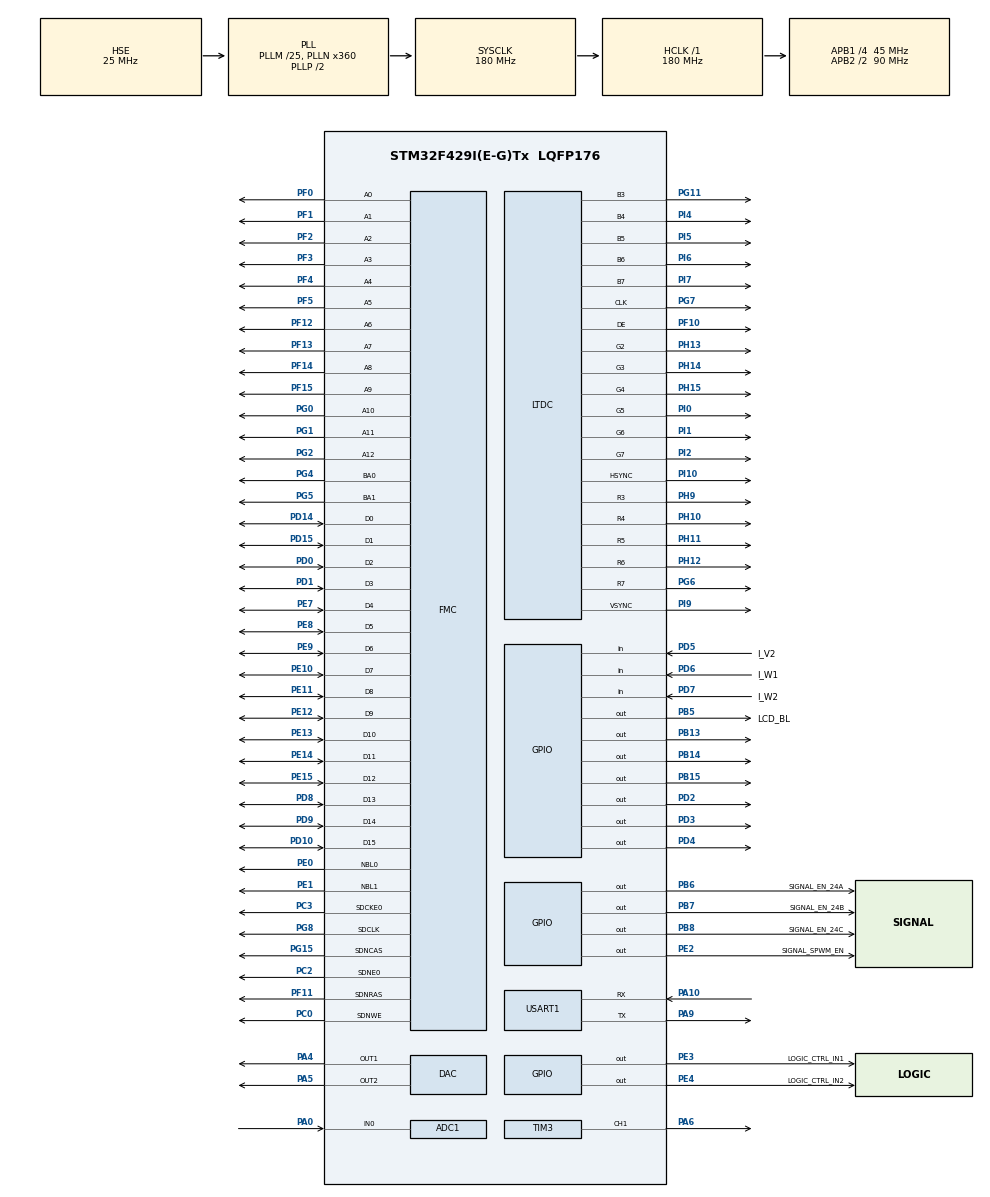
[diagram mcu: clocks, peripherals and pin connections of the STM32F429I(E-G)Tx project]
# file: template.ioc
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ADC1.Channel-0\#ChannelRegularConversion=ADC_CHANNEL_0
ADC1.ClockPrescaler=ADC_CLOCK_SYNC_PCLK_DIV6
ADC1.ContinuousConvMode=DISABLE
ADC1.DMAContinuousRequests=ENABLE
ADC1.EOCSelection=ADC_EOC_SEQ_CONV
ADC1.ExternalTrigConv=ADC_EXTERNALTRIGCONV_T2_TRGO
ADC1.NbrOfConversion=1
ADC1.NbrOfConversionFlag=1
ADC1.Rank-0\#ChannelRegularConversion=1
ADC1.SamplingTime-0\#ChannelRegularConversion=ADC_SAMPLETIME_56CYCLES
ADC1.ScanConvMode=ENABLE
ADC1.master=1
DAC.DAC_Trigger=DAC_TRIGGER_NONE
Dma.ADC1.0.Direction=DMA_PERIPH_TO_MEMORY
Dma.ADC1.0.FIFOMode=DMA_FIFOMODE_DISABLE
Dma.ADC1.0.Instance=DMA2_Stream0
Dma.ADC1.0.MemDataAlignment=DMA_MDATAALIGN_HALFWORD
Dma.ADC1.0.MemInc=DMA_MINC_ENABLE
Dma.ADC1.0.Mode=DMA_CIRCULAR
Dma.ADC1.0.PeriphDataAlignment=DMA_PDATAALIGN_HALFWORD
Dma.ADC1.0.PeriphInc=DMA_PINC_DISABLE
Dma.ADC1.0.Priority=DMA_PRIORITY_HIGH
Dma.Request0=ADC1
FATFS._CODE_PAGE=437
FATFS._FS_NORTC=1
FATFS._MAX_LFN=255
FATFS._MAX_SS=4096
FATFS._MIN_SS=4096
FATFS._NORTC_MDAY=7
FATFS._NORTC_YEAR=2022
FATFS._STRF_ENCODE=3
FATFS._USE_LFN=2
FMC.CASLatency1=FMC_SDRAM_CAS_LATENCY_3
FMC.ColumnBitsNumber1=FMC_SDRAM_COLUMN_BITS_NUM_9
FMC.ExitSelfRefreshDelay1=8
FMC.LoadToActiveDelay1=2
FMC.RCDDelay1=2
FMC.RPDelay1=2
FMC.RPDelay2=2
FMC.ReadBurst1=FMC_SDRAM_RBURST_ENABLE
FMC.ReadBurst2=FMC_SDRAM_RBURST_ENABLE
FMC.ReadPipeDelay1=FMC_SDRAM_RPIPE_DELAY_1
FMC.ReadPipeDelay2=FMC_SDRAM_RPIPE_DELAY_1
FMC.RowCycleDelay1=6
FMC.RowCycleDelay2=6
FMC.SDClockPeriod1=FMC_SDRAM_CLOCK_PERIOD_2
FMC.SDClockPeriod2=FMC_SDRAM_CLOCK_PERIOD_2
FMC.SelfRefreshTime1=6
FMC.WriteRecoveryTime1=4
FREERTOS.BinarySemaphores01=myBinarySemAnalog,Dynamic,NULL
FREERTOS.Tasks01=touchGFX,1,4096,TouchGFX_Task,As weak,NULL,Dynamic,NULL,NULL;myTask02,0,2048,StartTask02,Default,NULL,Dynamic,NULL,NULL
FREERTOS.Timers01=myTimer01,Callback01,osTimerPeriodic,Default,NULL,Dynamic,NULL
FREERTOS.configTOTAL_HEAP_SIZE=32768
LTDC.ActiveH=600
LTDC.ActiveW=1024
LTDC.Alpha_L0=255
LTDC.FBStartAdress_L0=0xC0000000
LTDC.HBP=140
LTDC.HFP=160
LTDC.HSync=20
LTDC.ImageHeight_L0=600
LTDC.ImageWidth_L0=1024
LTDC.Layers=0
LTDC.PixelFormat_L0=LTDC_PIXEL_FORMAT_RGB565
LTDC.VBP=20
LTDC.VFP=12
LTDC.VSync=3
LTDC.WindowX1_L0=1024
LTDC.WindowY1_L0=600
Mcu.Family=STM32F4
Mcu.Name=STM32F429I(E-G)Tx
Mcu.Package=LQFP176
NVIC.ADC_IRQn=true\:5\:0\:false\:false\:true\:true\:true\:true\:true
NVIC.DMA2D_IRQn=true\:5\:0\:false\:false\:true\:true\:true\:true\:true
NVIC.DMA2_Stream0_IRQn=true\:9\:0\:true\:false\:true\:false\:false\:true\:true
NVIC.LTDC_IRQn=true\:9\:0\:true\:false\:true\:true\:true\:true\:true
NVIC.PriorityGroup=NVIC_PRIORITYGROUP_4
NVIC.TIM6_DAC_IRQn=true\:5\:0\:false\:false\:true\:false\:true\:true\:true
NVIC.TIM7_IRQn=true\:15\:0\:false\:false\:true\:false\:false\:true\:true
NVIC.TimeBase=TIM7_IRQn
NVIC.TimeBaseIP=TIM7
PA0/WKUP.Signal=ADCx_IN0
PA10.Mode=Asynchronous
PA10.Signal=USART1_RX
PA13.Mode=Serial_Wire
PA13.Signal=SYS_JTMS-SWDIO
PA14.Mode=Serial_Wire
PA14.Signal=SYS_JTCK-SWCLK
PA4.Signal=COMP_DAC1_group
PA5.Signal=COMP_DAC2_group
PA6.Signal=S_TIM3_CH1
PA9.Mode=Asynchronous
PA9.Signal=USART1_TX
PB13.Signal=GPIO_Output
PB14.Signal=GPIO_Output
PB15.Signal=GPIO_Output
PB5.GPIO_Label=LCD_BL
PB5.GPIO_Speed=GPIO_SPEED_FREQ_HIGH
PB5.Signal=GPIO_Output
PB6.GPIO_Label=SIGNAL_EN_24A
PB6.GPIO_Speed=GPIO_SPEED_FREQ_HIGH
PB6.Signal=GPIO_Output
PB7.GPIO_Label=SIGNAL_EN_24B
PB7.GPIO_Speed=GPIO_SPEED_FREQ_HIGH
PB7.Signal=GPIO_Output
PB8.GPIO_Label=SIGNAL_EN_24C
PB8.GPIO_Speed=GPIO_SPEED_FREQ_HIGH
PB8.Signal=GPIO_Output
PC0.Signal=FMC_SDNWE
PC14/OSC32_IN.Mode=LSE-External-Oscillator
PC14/OSC32_IN.Signal=RCC_OSC32_IN
PC15/OSC32_OUT.Mode=LSE-External-Oscillator
PC15/OSC32_OUT.Signal=RCC_OSC32_OUT
PC2.Mode=SdramChipSelect1_1
PC2.Signal=FMC_SDNE0
PC3.Mode=SdramChipSelect1_1
PC3.Signal=FMC_SDCKE0
PD0.Signal=FMC_D2_DA2
PD1.Signal=FMC_D3_DA3
PD10.Signal=FMC_D15_DA15
PD14.Signal=FMC_D0_DA0
PD15.Signal=FMC_D1_DA1
PD2.Signal=GPIO_Output
PD3.Signal=GPIO_Output
PD4.Signal=GPIO_Output
PD5.GPIO_Label=I_V2
PD5.Signal=GPIO_Input
PD6.GPIO_Label=I_W1
PD6.Signal=GPIO_Input
PD7.GPIO_Label=I_W2
PD7.Signal=GPIO_Input
PD8.Signal=FMC_D13_DA13
PD9.Signal=FMC_D14_DA14
PE0.Signal=FMC_NBL0
PE1.Signal=FMC_NBL1
PE10.Signal=FMC_D7_DA7
PE11.Signal=FMC_D8_DA8
PE12.Signal=FMC_D9_DA9
PE13.Signal=FMC_D10_DA10
PE14.Signal=FMC_D11_DA11
PE15.Signal=FMC_D12_DA12
PE2.GPIO_Label=SIGNAL_SPWM_EN
PE2.GPIO_Speed=GPIO_SPEED_FREQ_HIGH
PE2.Signal=GPIO_Output
PE3.GPIO_Label=LOGIC_CTRL_IN1
PE3.GPIO_Speed=GPIO_SPEED_FREQ_HIGH
PE3.Signal=GPIO_Output
PE4.GPIO_Label=LOGIC_CTRL_IN2
PE4.GPIO_Speed=GPIO_SPEED_FREQ_HIGH
PE4.Signal=GPIO_Output
PE7.Signal=FMC_D4_DA4
PE8.Signal=FMC_D5_DA5
PE9.Signal=FMC_D6_DA6
PF0.Signal=FMC_A0
PF1.Signal=FMC_A1
PF10.GPIO_Speed=GPIO_SPEED_FREQ_VERY_HIGH
PF10.Mode=RGB565
PF10.Signal=LTDC_DE
PF11.Signal=FMC_SDNRAS
PF12.Signal=FMC_A6
PF13.Signal=FMC_A7
PF14.Signal=FMC_A8
PF15.Signal=FMC_A9
PF2.Signal=FMC_A2
PF3.Signal=FMC_A3
PF4.Signal=FMC_A4
PF5.Signal=FMC_A5
PG0.Signal=FMC_A10
PG1.Signal=FMC_A11
PG11.GPIO_Speed=GPIO_SPEED_FREQ_VERY_HIGH
PG11.Mode=RGB565
PG11.Signal=LTDC_B3
PG15.Signal=FMC_SDNCAS
PG2.Signal=FMC_A12
PG4.Signal=FMC_A14_BA0
PG5.Signal=FMC_A15_BA1
PG6.GPIO_Speed=GPIO_SPEED_FREQ_VERY_HIGH
PG6.Mode=RGB565
PG6.Signal=LTDC_R7
PG7.GPIO_Speed=GPIO_SPEED_FREQ_VERY_HIGH
PG7.Mode=RGB565
PG7.Signal=LTDC_CLK
PG8.Signal=FMC_SDCLK
PH0/OSC_IN.Mode=HSE-External-Oscillator
PH0/OSC_IN.Signal=RCC_OSC_IN
PH1/OSC_OUT.Mode=HSE-External-Oscillator
PH1/OSC_OUT.Signal=RCC_OSC_OUT
PH10.GPIO_Speed=GPIO_SPEED_FREQ_VERY_HIGH
PH10.Mode=RGB565
PH10.Signal=LTDC_R4
PH11.GPIO_Speed=GPIO_SPEED_FREQ_VERY_HIGH
PH11.Mode=RGB565
PH11.Signal=LTDC_R5
PH12.GPIO_Speed=GPIO_SPEED_FREQ_VERY_HIGH
PH12.Mode=RGB565
PH12.Signal=LTDC_R6
PH13.GPIO_Speed=GPIO_SPEED_FREQ_VERY_HIGH
PH13.Mode=RGB565
PH13.Signal=LTDC_G2
PH14.GPIO_Speed=GPIO_SPEED_FREQ_VERY_HIGH
PH14.Mode=RGB565
PH14.Signal=LTDC_G3
PH15.GPIO_Speed=GPIO_SPEED_FREQ_VERY_HIGH
PH15.Mode=RGB565
PH15.Signal=LTDC_G4
PH9.GPIO_Speed=GPIO_SPEED_FREQ_VERY_HIGH
PH9.Mode=RGB565
PH9.Signal=LTDC_R3
PI0.GPIO_Speed=GPIO_SPEED_FREQ_VERY_HIGH
PI0.Mode=RGB565
PI0.Signal=LTDC_G5
PI1.GPIO_Speed=GPIO_SPEED_FREQ_VERY_HIGH
PI1.Mode=RGB565
PI1.Signal=LTDC_G6
PI10.GPIO_Speed=GPIO_SPEED_FREQ_VERY_HIGH
PI10.Mode=RGB565
PI10.Signal=LTDC_HSYNC
PI2.GPIO_Speed=GPIO_SPEED_FREQ_VERY_HIGH
PI2.Mode=RGB565
PI2.Signal=LTDC_G7
PI4.GPIO_Speed=GPIO_SPEED_FREQ_VERY_HIGH
PI4.Mode=RGB565
PI4.Signal=LTDC_B4
PI5.GPIO_Speed=GPIO_SPEED_FREQ_VERY_HIGH
PI5.Mode=RGB565
PI5.Signal=LTDC_B5
PI6.GPIO_Speed=GPIO_SPEED_FREQ_VERY_HIGH
PI6.Mode=RGB565
PI6.Signal=LTDC_B6
PI7.GPIO_Speed=GPIO_SPEED_FREQ_VERY_HIGH
PI7.Mode=RGB565
PI7.Signal=LTDC_B7
PI9.GPIO_Speed=GPIO_SPEED_FREQ_VERY_HIGH
PI9.Mode=RGB565
PI9.Signal=LTDC_VSYNC
ProjectManager.HeapSize=0x1000
ProjectManager.StackSize=0x2000
ProjectManager.TargetToolchain=MDK-ARM V5
RCC.48MHZClocksFreq_Value=45000000
RCC.AHBFreq_Value=180000000
RCC.APB1CLKDivider=RCC_HCLK_DIV4
RCC.APB1Freq_Value=45000000
RCC.APB1TimFreq_Value=90000000
RCC.APB2CLKDivider=RCC_HCLK_DIV2
RCC.APB2Freq_Value=90000000
RCC.APB2TimFreq_Value=180000000
RCC.CortexFreq_Value=180000000
RCC.HCLKFreq_Value=180000000
RCC.HSE_VALUE=25000000
RCC.HSI_VALUE=16000000
RCC.PLLM=25
RCC.PLLN=360
RCC.PLLQ=8
RCC.PLLSAIN=168
RCC.PLLSourceVirtual=RCC_PLLSOURCE_HSE
RCC.SYSCLKFreq_VALUE=180000000
RCC.SYSCLKSource=RCC_SYSCLKSOURCE_PLLCLK
RCC.VCOOutputFreq_Value=360000000
SH.ADCx_IN0.0=ADC1_IN0,IN0
SH.COMP_DAC1_group.0=DAC_OUT1,DAC_OUT1
SH.COMP_DAC2_group.0=DAC_OUT2,DAC_OUT2
SH.FMC_A0.0=FMC_A0,13b-sda1
SH.FMC_A1.0=FMC_A1,13b-sda1
SH.FMC_A10.0=FMC_A10,13b-sda1
SH.FMC_A11.0=FMC_A11,13b-sda1
SH.FMC_A12.0=FMC_A12,13b-sda1
SH.FMC_A14_BA0.0=FMC_BA0,FourSdramBanks1
SH.FMC_A15_BA1.0=FMC_BA1,FourSdramBanks1
SH.FMC_A2.0=FMC_A2,13b-sda1
SH.FMC_A3.0=FMC_A3,13b-sda1
SH.FMC_A4.0=FMC_A4,13b-sda1
SH.FMC_A5.0=FMC_A5,13b-sda1
SH.FMC_A6.0=FMC_A6,13b-sda1
SH.FMC_A7.0=FMC_A7,13b-sda1
SH.FMC_A8.0=FMC_A8,13b-sda1
SH.FMC_A9.0=FMC_A9,13b-sda1
SH.FMC_D0_DA0.0=FMC_D0,sd-16b-d1
SH.FMC_D10_DA10.0=FMC_D10,sd-16b-d1
SH.FMC_D11_DA11.0=FMC_D11,sd-16b-d1
SH.FMC_D12_DA12.0=FMC_D12,sd-16b-d1
SH.FMC_D13_DA13.0=FMC_D13,sd-16b-d1
SH.FMC_D14_DA14.0=FMC_D14,sd-16b-d1
SH.FMC_D15_DA15.0=FMC_D15,sd-16b-d1
SH.FMC_D1_DA1.0=FMC_D1,sd-16b-d1
SH.FMC_D2_DA2.0=FMC_D2,sd-16b-d1
SH.FMC_D3_DA3.0=FMC_D3,sd-16b-d1
SH.FMC_D4_DA4.0=FMC_D4,sd-16b-d1
SH.FMC_D5_DA5.0=FMC_D5,sd-16b-d1
SH.FMC_D6_DA6.0=FMC_D6,sd-16b-d1
SH.FMC_D7_DA7.0=FMC_D7,sd-16b-d1
SH.FMC_D8_DA8.0=FMC_D8,sd-16b-d1
SH.FMC_D9_DA9.0=FMC_D9,sd-16b-d1
SH.FMC_NBL0.0=FMC_NBL0,Sd2ByteEnable1
SH.FMC_NBL1.0=FMC_NBL1,Sd2ByteEnable1
SH.FMC_SDCLK.0=FMC_SDCLK,13b-sda1
SH.FMC_SDNCAS.0=FMC_SDNCAS,13b-sda1
SH.FMC_SDNRAS.0=FMC_SDNRAS,13b-sda1
SH.FMC_SDNWE.0=FMC_SDNWE,13b-sda1
SH.S_TIM3_CH1.0=TIM3_CH1,PWM Generation1 CH1
STMicroelectronics.X-CUBE-TOUCHGFX.4.18.1.ApplicationCcGraphicsJjApplication=TouchGFXOoGenerator
STMicroelectronics.X-CUBE-TOUCHGFX.4.18.1.tgfx_address1=0xC0000000
STMicroelectronics.X-CUBE-TOUCHGFX.4.18.1.tgfx_address2=0xC012C000
STMicroelectronics.X-CUBE-TOUCHGFX.4.18.1.tgfx_buffering_strategy=Double
STMicroelectronics.X-CUBE-TOUCHGFX.4.18.1.tgfx_display_interface=disp_ltdc
STMicroelectronics.X-CUBE-TOUCHGFX.4.18.1.tgfx_hardware_accelerator=dma_2d
STMicroelectronics.X-CUBE-TOUCHGFX.4.18.1.tgfx_location=By Address
STMicroelectronics.X-CUBE-TOUCHGFX.4.18.1.tgfx_vsync=vsync_ltdc
TIM2.Period=839
TIM2.TIM_MasterOutputTrigger=TIM_TRGO_UPDATE
TIM3.Channel-PWM\ Generation1\ CH1=TIM_CHANNEL_1
TIM3.Period=999
TIM3.Prescaler=90
TIM3.Pulse-PWM\ Generation1\ CH1=500
USART1.VirtualMode=VM_ASYNC
VP_CRC_VS_CRC.Mode=CRC_Activate
VP_DMA2D_VS_DMA2D.Mode=DMA2D_Activate
VP_FATFS_VS_Generic.Mode=User_defined
VP_FREERTOS_VS_CMSIS_V1.Mode=CMSIS_V1
VP_RNG_VS_RNG.Mode=RNG_Activate
VP_STMicroelectronics.X-CUBE-TOUCHGFX_VS_GraphicsJjApplication_4.18.1.Mode=GraphicsJjApplication
VP_SYS_VS_tim7.Mode=TIM7
VP_TIM2_VS_ClockSourceINT.Mode=Internal
VP_TIM3_VS_ClockSourceINT.Mode=Internal
board=custom

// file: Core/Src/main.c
/* USER CODE BEGIN Header */
/**
 ******************************************************************************
 * @file           : main.c
 * @brief          : Main program body
 ******************************************************************************
 * @attention
 *
 * <h2><center>&copy; Copyright (c) 2021 STMicroelectronics.
 * All rights reserved.</center></h2>
 *
 * This software component is licensed by ST under Ultimate Liberty license
 * SLA0044, the "License"; You may not use this file except in compliance with
 * the License. You may obtain a copy of the License at:
 *                             www.st.com/SLA0044
 *
 ******************************************************************************
 */
/* USER CODE END Header */
#include "main.h"
#include "cmsis_os.h"
#include "adc.h"
#include "crc.h"
#include "dac.h"
#include "dma.h"
#include "dma2d.h"
#include "fatfs.h"
#include "ltdc.h"
#include "rng.h"
#include "tim.h"
#include "usart.h"
#include "gpio.h"
#include "fmc.h"
#include "app_touchgfx.h"

/* USER CODE BEGIN Includes */
#include "spwm.h"
#include "w25qxx.h"
#include "history.h"
/* USER CODE END Includes */

/* USER CODE BEGIN PTD */
/* USER CODE BEGIN PV */
uint16_t adc_buf[ADC_BUF_LEN];
/* USER CODE END PV */

/* USER CODE END PTD */

/* USER CODE BEGIN PV */
uint16_t adc_buf[ADC_BUF_LEN];
/* USER CODE END PV */

void SystemClock_Config(void);
void MX_FREERTOS_Init(void);

int main(void)
{

  /* MCU Configuration--------------------------------------------------------*/

  /* Reset of all peripherals, Initializes the Flash interface and the Systick. */
  HAL_Init();

  /* Configure the system clock */
  SystemClock_Config();

  /* Initialize all configured peripherals */
  MX_GPIO_Init();
  MX_DMA_Init();
  MX_FMC_Init();
  MX_CRC_Init();
  MX_LTDC_Init();
  MX_USART1_UART_Init();
  MX_DMA2D_Init();
  MX_ADC1_Init();
  MX_TIM3_Init();
  MX_FATFS_Init();
  MX_RNG_Init();
  MX_DAC_Init();
  MX_TIM2_Init();
  MX_TouchGFX_Init();
  /* USER CODE BEGIN 2 */
	HAL_ADC_Start_DMA(&hadc1, (uint32_t*)adc_buf, 4096);
HAL_TIM_Base_Start(&htim2);
HAL_TIM_PWM_Start(&htim3, TIM_CHANNEL_1);

  page_Init();
  spwm_init();

  /* USER CODE END 2 */

  /* Call init function for freertos objects (in freertos.c) */
  MX_FREERTOS_Init();
  /* Start scheduler */
  osKernelStart();

  /* We should never get here as control is now taken by the scheduler */
  /* Infinite loop */
  while (1)
  {

  }
}

void SystemClock_Config(void)
{
  RCC_OscInitTypeDef RCC_OscInitStruct = {0};
  RCC_ClkInitTypeDef RCC_ClkInitStruct = {0};

  /** Configure the main internal regulator output voltage
  */
  __HAL_RCC_PWR_CLK_ENABLE();
  __HAL_PWR_VOLTAGESCALING_CONFIG(PWR_REGULATOR_VOLTAGE_SCALE1);
  /** Initializes the RCC Oscillators according to the specified parameters
  * in the RCC_OscInitTypeDef structure.
  */
  RCC_OscInitStruct.OscillatorType = RCC_OSCILLATORTYPE_HSE;
  RCC_OscInitStruct.HSEState = RCC_HSE_ON;
  RCC_OscInitStruct.PLL.PLLState = RCC_PLL_ON;
  RCC_OscInitStruct.PLL.PLLSource = RCC_PLLSOURCE_HSE;
  RCC_OscInitStruct.PLL.PLLM = 25;
  RCC_OscInitStruct.PLL.PLLN = 360;
  RCC_OscInitStruct.PLL.PLLP = RCC_PLLP_DIV2;
  RCC_OscInitStruct.PLL.PLLQ = 8;
  if (HAL_RCC_OscConfig(&RCC_OscInitStruct) != HAL_OK)
  {
    Error_Handler();
  }
  /** Activate the Over-Drive mode
  */
  if (HAL_PWREx_EnableOverDrive() != HAL_OK)
  {
    Error_Handler();
  }
  /** Initializes the CPU, AHB and APB buses clocks
  */
  RCC_ClkInitStruct.ClockType = RCC_CLOCKTYPE_HCLK|RCC_CLOCKTYPE_SYSCLK
                              |RCC_CLOCKTYPE_PCLK1|RCC_CLOCKTYPE_PCLK2;
  RCC_ClkInitStruct.SYSCLKSource = RCC_SYSCLKSOURCE_PLLCLK;
  RCC_ClkInitStruct.AHBCLKDivider = RCC_SYSCLK_DIV1;
  RCC_ClkInitStruct.APB1CLKDivider = RCC_HCLK_DIV4;
  RCC_ClkInitStruct.APB2CLKDivider = RCC_HCLK_DIV2;

  if (HAL_RCC_ClockConfig(&RCC_ClkInitStruct, FLASH_LATENCY_5) != HAL_OK)
  {
    Error_Handler();
  }
}

void HAL_TIM_PeriodElapsedCallback(TIM_HandleTypeDef *htim)
{
  if (htim->Instance == TIM7) {
    HAL_IncTick();
  }
}

void Error_Handler(void)
{
  __disable_irq();
  while (1)
  {
  }
}

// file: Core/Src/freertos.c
/* USER CODE BEGIN Header */
/**
 ******************************************************************************
 * File Name          : freertos.c
 * Description        : Code for freertos applications
 ******************************************************************************
 * @attention
 *
 * <h2><center>&copy; Copyright (c) 2021 STMicroelectronics.
 * All rights reserved.</center></h2>
 *
 * This software component is licensed by ST under Ultimate Liberty license
 * SLA0044, the "License"; You may not use this file except in compliance with
 * the License. You may obtain a copy of the License at:
 *                             www.st.com/SLA0044
 *
 ******************************************************************************
 */
/* USER CODE END Header */

#include "FreeRTOS.h"
#include "task.h"
#include "main.h"
#include "cmsis_os.h"

/* USER CODE BEGIN Includes */
#include "spwm.h"
#include "tim.h"
#include "adc.h"
#include "dac.h"
/* USER CODE END Includes */

/* USER CODE BEGIN Variables */

uint16_t uADCValue[40]={0};
/* USER CODE END Variables */
osThreadId touchGFXHandle;
osThreadId myTask02Handle;
osSemaphoreId myBinarySemAnalogHandle;

void TouchGFX_Task(void const * argument);
void StartTask02(void const * argument);

void MX_FREERTOS_Init(void); /* (MISRA C 2004 rule 8.1) */

/* GetIdleTaskMemory prototype (linked to static allocation support) */
void vApplicationGetIdleTaskMemory( StaticTask_t **ppxIdleTaskTCBBuffer, StackType_t **ppxIdleTaskStackBuffer, uint32_t *pulIdleTaskStackSize );

/* USER CODE BEGIN GET_IDLE_TASK_MEMORY */
static StaticTask_t xIdleTaskTCBBuffer;
static StackType_t xIdleStack[configMINIMAL_STACK_SIZE];

void vApplicationGetIdleTaskMemory(StaticTask_t **ppxIdleTaskTCBBuffer, StackType_t **ppxIdleTaskStackBuffer, uint32_t *pulIdleTaskStackSize)
{
  *ppxIdleTaskTCBBuffer = &xIdleTaskTCBBuffer;
  *ppxIdleTaskStackBuffer = &xIdleStack[0];
  *pulIdleTaskStackSize = configMINIMAL_STACK_SIZE;
  /* place for user code */
}
/* USER CODE END GET_IDLE_TASK_MEMORY */

void MX_FREERTOS_Init(void) {

  /* Create the semaphores(s) */
  /* definition and creation of myBinarySemAnalog */
  osSemaphoreDef(myBinarySemAnalog);
  myBinarySemAnalogHandle = osSemaphoreCreate(osSemaphore(myBinarySemAnalog), 1);

  /* Create the thread(s) */
  /* definition and creation of touchGFX */
  osThreadDef(touchGFX, TouchGFX_Task, osPriorityAboveNormal, 0, 4096);
  touchGFXHandle = osThreadCreate(osThread(touchGFX), NULL);

  /* definition and creation of myTask02 */
  osThreadDef(myTask02, StartTask02, osPriorityNormal, 0, 2048);
  myTask02Handle = osThreadCreate(osThread(myTask02), NULL);

}

__weak void TouchGFX_Task(void const * argument)
{
  for (;;)
  {
    osDelay(1);
  }
}

void StartTask02(void const * argument)
{
  /* USER CODE BEGIN StartTask02 */
  /* Infinite loop */

  for (;;)
  {
    osDelay(10);//10ms
  }
  /* USER CODE END StartTask02 */
}

/* USER CODE BEGIN Application */
void HAL_ADC_ConvCpltCallback(ADC_HandleTypeDef* hadc)
{
  if (hadc->Instance != ADC1)
  {
    return;
  }

  TIM1_ProcessAdcSamples(&adc_buf[ADC_BUF_LEN / 2U], ADC_BUF_LEN / 2U);
  osSemaphoreRelease(myBinarySemAnalogHandle);
}

void HAL_ADC_ConvHalfCpltCallback(ADC_HandleTypeDef* hadc)
{
  if (hadc->Instance != ADC1)
  {
    return;
  }

  TIM1_ProcessAdcSamples(adc_buf, ADC_BUF_LEN / 2U);
}
/* USER CODE END Application */
